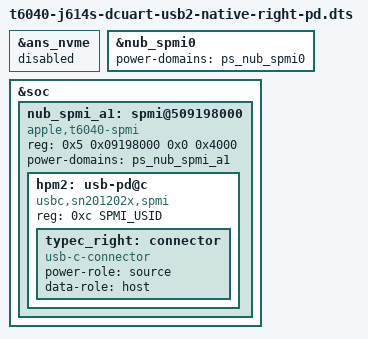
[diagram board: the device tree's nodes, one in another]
// SPDX-License-Identifier: GPL-2.0+ OR MIT
/*
 * REVIEW CANDIDATE — DO NOT BOOT BEFORE INDEPENDENT EXACT-ARTIFACT REVIEW.
 *
 * T6040 J614s: the usb2-native-right fixture plus the right-port Type-C PD
 * controller (SN201202x on Apple SPMI), bound to the tps6598x SPMI transport
 * (patches/0001-usb-typec-tps6598x-add-SPMI-transport-for-T6040-SN20.patch,
 * T6040_TYPEC_PD=1).
 *
 * CJ signed off the enumerated SPMI transaction envelope on 2026-08-19:
 * probe does WAKEUP + reads + SSPS-to-S0, INT_MASK1 (0x16) write at probe,
 * and W1C INT_CLEAR1 (0x18) per event. SPMI_SAFETY.md keeps every live SPMI
 * experiment attended and review-gated. The remaining gate is independent
 * exact-artifact review of the corrected physical address below.
 *
 * Scope guard, per SPMI_SAFETY.md: this file describes EXACTLY ONE HPM —
 * right-port hpm2 on nub-spmi-a1. The ADT raw /arm-io reg0 is 0x309198000,
 * translated through /arm-io ranges to CPU physical 0x509198000; generation
 * 3, child SID 0x0c, rid 2, port-number 3. The a0 bus and the other three PD
 * controllers are deliberately not described; the tps6598x SPMI driver binds
 * by compatible, so the DT is the entire endpoint gate.
 *
 * Deliberate omissions, each a decision not an oversight:
 *  - No interrupts property: the ADT routes HPM interrupts through paths we
 *    have not reviewed; tipd falls back to 500 ms polling (core.c
 *    POLL_INTERVAL), which the attended first run prefers anyway — every
 *    event surfaces as a logged poll cycle, not an async path.
 *  - No ports/OF-graph under the connector: the fixture forces host mode
 *    (apple,force-host-mode), there is no role switch to wire;
 *    fwnode_usb_role_switch_get() returns NULL and probe proceeds.
 *  - power-role "source", data-role "host": the minimal statement of what
 *    the run intends (source VBUS to a bus-powered stick), not "dual" —
 *    keeps the typec class from ever asking for a swap.
 *  - The controller carries ps_nub_spmi_a1. Ticket 305 runs 1/2 proved the
 *    nub domains do not reliably arrive on; pd_ignore_unused is insufficient.
 */

#include "t6040-j614s-dcuart-wifi-usb2-native-right.dts"
#include <dt-bindings/spmi/spmi.h>

/*
 * The PD-capable kernel is built by the current kbuild script, whose
 * integrated profile promotes NVMe to =y (daily-v3). Ticket 227's
 * dead-controller teardown kills all block I/O, which must not fire inside
 * a Type-C PD experiment — force the node off in this fixture regardless
 * of what the included wifi.dts says.
 */
&ans_nvme {
	status = "disabled";
};

/*
 * v2 (2026-08-19, run-1/run-2 hang fix): SPMI controllers need their pmgr
 * domains. The nub power area is NOT reliably on at boot on T6040 (the
 * kernel itself logs "always-on domain nub_ocla is not on at boot"), and
 * neither nub_spmi0 (t6040.dtsi) nor the a1 node below carried
 * power-domains — so the first spmi-apple MMIO into the ungated AHB hung
 * the boot silently at ~0.15 s until the watchdog reset (runs 1 and 2,
 * panel-photo diagnosis). M1 never hit this because its nub domain happens
 * to be on at boot. v1 of this file called the omission deliberate; that
 * reasoning ("pd_ignore_unused; m1n1 drove the block bare") was wrong —
 * pd_ignore_unused only keeps ON domains on, and m1n1 ran with
 * macOS-warm power.
 */
&nub_spmi0 {
	power-domains = <&ps_nub_spmi0>;
};

&soc {
	/*
	 * ADT /arm-io/nub-spmi-a1 (compatible aapl,spmi, generation 3):
	 * raw reg[0] = 0x309198000/0x4000, translated CPU physical address =
	 * 0x509198000/0x4000. Linux /soc has identity ranges, so its reg must use
	 * the translated address. Ticket 305 runs 1-4 accidentally used the raw
	 * value and therefore never touched the real controller (ticket 3000).
	 */
	/*
	 * Ticket 3008 restores the single hpm2 endpoint at the corrected physical
	 * address. This remains an offline candidate until another agent verifies
	 * the DTB and the complete ticket-305 fixture.
	 */
	nub_spmi_a1: spmi@509198000 {
		compatible = "apple,t6040-spmi", "apple,spmi";
		reg = <0x5 0x09198000 0x0 0x4000>;
		power-domains = <&ps_nub_spmi_a1>;
		#address-cells = <2>;
		#size-cells = <0>;
		status = "okay";

		/* ADT /arm-io/nub-spmi-a1/hpm2 — the RIGHT Type-C port. */
		hpm2: usb-pd@c {
			compatible = "usbc,sn201202x,spmi";
			reg = <0xc SPMI_USID>;

			typec_right: connector {
				compatible = "usb-c-connector";
				power-role = "source";
				data-role = "host";
			};
		};
	};
};
